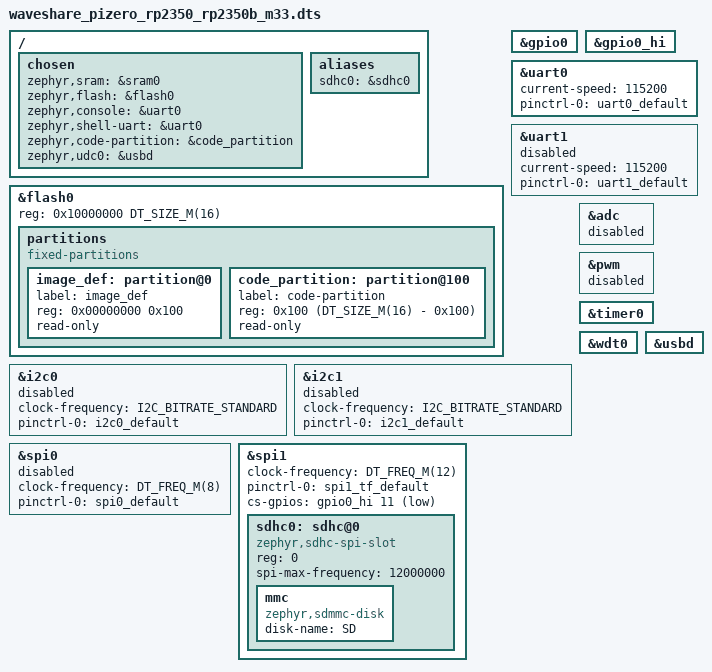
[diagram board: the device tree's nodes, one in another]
/*
 * Copyright (c) 2026 Nono
 *
 * SPDX-License-Identifier: Apache-2.0
 */

/dts-v1/;

/* The build system assumes that there's a cpucluster-specific file.
*
* This file provides composition of the device tree:
* 1. The common features of the SoC
* 2. Core-specific configuration.
* 3. Board-specific configuration.
*/
#include <freq.h>
#include <zephyr/dt-bindings/gpio/gpio.h>
#include <zephyr/dt-bindings/i2c/i2c.h>

#include <raspberrypi/rpi_pico/rp2350b.dtsi>
#include <raspberrypi/rpi_pico/m33.dtsi>

#include "waveshare_pizero_rp2350-pinctrl.dtsi"

/ {
	chosen {
		zephyr,sram = &sram0;
		zephyr,flash = &flash0;
		zephyr,console = &uart0;
		zephyr,shell-uart = &uart0;
		zephyr,code-partition = &code_partition;
		zephyr,udc0 = &usbd;
	};

	aliases {
		sdhc0 = &sdhc0;
	};
};

&flash0 {
	reg = <0x10000000 DT_SIZE_M(16)>;

	partitions {
		compatible = "fixed-partitions";
		#address-cells = <1>;
		#size-cells = <1>;

		/* Reserved memory for an image definition block. The block is much
		 * smaller than 256 bytes, but in practice the linker places the vector
		 * table at a much larger alignment offset.
		 */
		image_def: partition@0 {
			label = "image_def";
			reg = <0x00000000 0x100>;
			read-only;
		};

		/*
		 * Usable flash. Starts at 0x100, after the image definition block.
		 * The partition size is 16MB minus the 0x100 bytes taken by the
		 * image definition.
		 */
		code_partition: partition@100 {
			label = "code-partition";
			reg = <0x100 (DT_SIZE_M(16) - 0x100)>;
			read-only;
		};
	};
};

&gpio0 {
	status = "okay";
};

&gpio0_hi {
	status = "okay";
};

&uart0 {
	current-speed = <115200>;
	status = "okay";
	pinctrl-0 = <&uart0_default>;
	pinctrl-names = "default";
};

&uart1 {
	current-speed = <115200>;
	status = "disabled";
	pinctrl-0 = <&uart1_default>;
	pinctrl-names = "default";
};

&i2c0 {
	clock-frequency = <I2C_BITRATE_STANDARD>;
	status = "disabled";
	pinctrl-0 = <&i2c0_default>;
	pinctrl-names = "default";
};

&i2c1 {
	clock-frequency = <I2C_BITRATE_STANDARD>;
	status = "disabled";
	pinctrl-0 = <&i2c1_default>;
	pinctrl-names = "default";
};

&spi0 {
	clock-frequency = <DT_FREQ_M(8)>;
	status = "disabled";
	pinctrl-0 = <&spi0_default>;
	pinctrl-names = "default";
};

/*
 * Onboard microSD over SPI1 (GP30/31/40, CS on GP43).
 * Header SPI1 (GP10-13) uses &spi1_default; remux only if TF is unused.
 */
&spi1 {
	clock-frequency = <DT_FREQ_M(12)>;
	status = "okay";
	pinctrl-0 = <&spi1_tf_default>;
	pinctrl-names = "default";
	cs-gpios = <&gpio0_hi 11 GPIO_ACTIVE_LOW>; /* GP43 SD_CS / SDIO_D3 */

	sdhc0: sdhc@0 {
		compatible = "zephyr,sdhc-spi-slot";
		reg = <0>;
		status = "okay";
		spi-max-frequency = <12000000>;

		mmc {
			compatible = "zephyr,sdmmc-disk";
			disk-name = "SD";
			status = "okay";
		};
	};
};

&adc {
	status = "disabled";
};

&pwm {
	status = "disabled";
};

&timer0 {
	status = "okay";
};

&wdt0 {
	status = "okay";
};

zephyr_udc0: &usbd {
	status = "okay";
};
